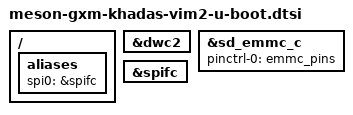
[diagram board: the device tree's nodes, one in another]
// SPDX-License-Identifier: (GPL-2.0+ OR MIT)
/*
 * Copyright (c) 2019 BayLibre, SAS.
 * Author: Neil Armstrong <narmstrong@baylibre.com>
 */

#include "meson-gxl-u-boot.dtsi"

/ {
	aliases {
		spi0 = &spifc;
	};
};

&dwc2 {
	status = "okay";
};

&sd_emmc_c {
	status = "okay";
	pinctrl-0 = <&emmc_pins>;
};

&spifc {
	status = "okay";
};
